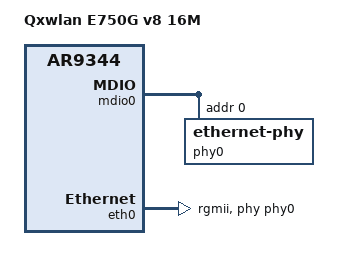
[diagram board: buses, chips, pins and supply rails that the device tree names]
// SPDX-License-Identifier: GPL-2.0-or-later OR MIT

#include "ar9344_qxwlan_e750x.dtsi"

/ {
	model = "Qxwlan E750G v8 16M";
	compatible = "qxwlan,e750g-v8-16m", "qca,ar9344";
};

&mdio0 {
	status = "okay";

	phy-mask = <0>;

	phy0: ethernet-phy@0 {
		reg = <0>;
		phy-mode = "rgmii";

		qca,ar8327-initvals = <
			0x04 0x07600000 /* PORT0 PAD MODE CTRL */
			0x10 0x81000080 /* POWER_ON_STRAP */
			0x50 0xcc35cc35 /* LED_CTRL0 */
			0x54 0xca35ca35 /* LED_CTRL1 */
			0x58 0xc935c935 /* LED_CTRL2 */
			0x5c 0x03ffff00 /* LED_CTRL3 */
			0x7c 0x0000007e /* PORT0_STATUS */
			>;
	};
};

&eth0 {
	status = "okay";

	pll-data = <0x06000000 0x00000101 0x00001616>;

	nvmem-cells = <&macaddr_pridata_400>;
	nvmem-cell-names = "mac-address";

	phy-mode = "rgmii";
	phy-handle = <&phy0>;
};

&partitions {
	partition@70000 {
		compatible = "denx,uimage";
		label = "firmware";
		reg = <0x070000 0xf90000>;
	};
};

&pridata {
	compatible = "nvmem-cells";
	#address-cells = <1>;
	#size-cells = <1>;

	macaddr_pridata_400: macaddr@400 {
		reg = <0x400 0x6>;
	};
};
